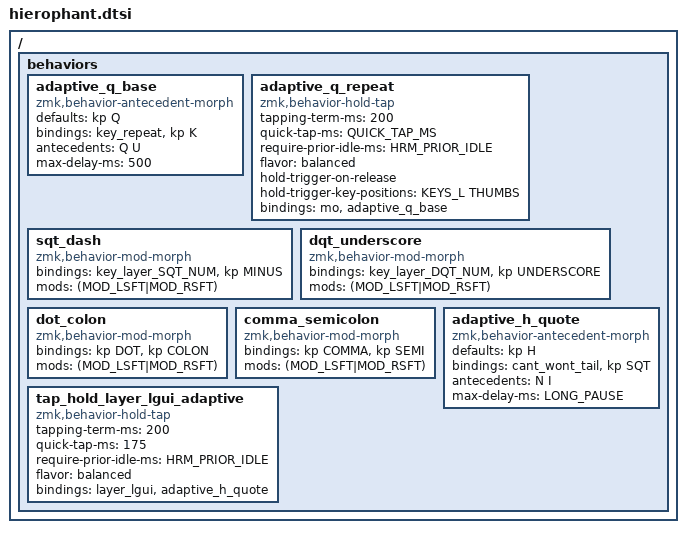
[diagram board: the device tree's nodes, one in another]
ZMK_SIMPLE_MACRO(cant_wont_tail, <&kp SQT>, <&kp T>)
ZMK_SIMPLE_MACRO(dot_slash, <&kp DOT>, <&kp FSLH>)
/ {
	
	/*

	won't, can't  (no NH in english)
	i'd, i'll, i've (no IH)
	they're (no YH)


	*/


	
	behaviors {

		// Q with U->K antecedent
		adaptive_q_base: adaptive_q_base {
			compatible = "zmk,behavior-antecedent-morph";
			#binding-cells = <0>;
			defaults = <&kp Q>;
			bindings = <&key_repeat>, <&kp K>;
			antecedents = <Q U>;
			max-delay-ms = <500>;
		};

		adaptive_q_repeat: adaptive_q_repeat {
			compatible = "zmk,behavior-hold-tap";
			#binding-cells = <2>;
			tapping-term-ms = <200>;
			quick-tap-ms = <QUICK_TAP_MS>;
			require-prior-idle-ms = <HRM_PRIOR_IDLE>;
			flavor = "balanced";
			hold-trigger-on-release;
			hold-trigger-key-positions = <KEYS_L THUMBS>;
			bindings = <&mo>, <&adaptive_q_base>;
		};


		// todo: use this to remake adaptive_q_repeat
		MAKE_ANTECEDENT_MORPH(adaptive_q_k, Q, K, U)

		MAKE_ADAPTIVE_REPEAT(adaptive_w_repeat, tlr, NUMPAD, W)

		MAKE_ADAPTIVE_REPEAT(adaptive_u_repeat, tll, SYMBOL, U)
		MAKE_ADAPTIVE_REPEAT(adaptive_d_repeat, tlr, SYMBOL, D)

		MAKE_ADAPTIVE_REPEAT(adaptive_z_repeat, tll_sticky, EXTRA, Z)
		MAKE_ADAPTIVE_REPEAT(adaptive_l_repeat, tlr_sticky, EXTRA, L)

		MAKE_ADAPTIVE_REPEAT(adaptive_f_repeat, tll_sticky, FN, F)
		MAKE_ADAPTIVE_REPEAT(adaptive_b_repeat, tlr_sticky, FN, B)
		
		MAKE_ADAPTIVE_REPEAT(adaptive_i_repeat, hml, LALT, I)
		MAKE_ADAPTIVE_REPEAT(adaptive_e_repeat, hml, LSHIFT, E)
		MAKE_ADAPTIVE_REPEAT(adaptive_a_repeat, hml, LCTRL, A)
		MAKE_ADAPTIVE_REPEAT(adaptive_p_repeat, tll, NUM, P)

		MAKE_ADAPTIVE_REPEAT(adaptive_g_repeat, tlr, NUM, G)
		MAKE_ADAPTIVE_REPEAT(adaptive_s_repeat, hmr, RCTRL, S)
		MAKE_ADAPTIVE_REPEAT(adaptive_t_repeat, hmr, RSHIFT, T)
		MAKE_ADAPTIVE_REPEAT(adaptive_r_repeat, hmr, RALT, R)

		sqt_dash: sqt_dash {
			compatible = "zmk,behavior-mod-morph";
			#binding-cells = <0>;
			bindings = <&key_layer_SQT_NUM>, <&kp MINUS>;
			mods = <(MOD_LSFT|MOD_RSFT)>;
		};

		dqt_underscore: dqt_underscore {
			compatible = "zmk,behavior-mod-morph";
			#binding-cells = <0>;
			bindings = <&key_layer_DQT_NUM>, <&kp UNDERSCORE>;
			mods = <(MOD_LSFT|MOD_RSFT)>;
		};

		dot_colon: dot_colon {
			compatible = "zmk,behavior-mod-morph";
			#binding-cells = <0>;
			bindings = <&kp DOT>, <&kp COLON>;
			mods = <(MOD_LSFT|MOD_RSFT)>;
		};

		/*
		 * Comma is just a comma. It used to emit ", " -- comma and a
		 * space in one tap -- which is right for prose and wrong
		 * everywhere else: every list in code, every CSV, every
		 * "a,b" argument had a space to take back out. The space now
		 * lives on the key next door, which only becomes a space when
		 * a comma has just been typed, so prose still costs two keys
		 * and nothing else pays for it.
		 */
		comma_semicolon: comma_semicolon {
			compatible = "zmk,behavior-mod-morph";
			#binding-cells = <0>;
			bindings = <&kp COMMA>, <&kp SEMI>;
			mods = <(MOD_LSFT|MOD_RSFT)>;
		};

		/*
		 * Y, but a space straight after a comma -- the same trick the
		 * symbol layer plays with ` becoming / after ~. Y sits next to
		 * the comma on the bottom row, and "y" never follows a comma
		 * in English without a space in between, so the letter loses
		 * nothing.
		 */
		MAKE_ANTECEDENT_MORPH(y_comma_space, Y, SPACE, COMMA)

		adaptive_h_quote: adaptive_h_quote {
			compatible = "zmk,behavior-antecedent-morph";
			#binding-cells = <0>;
			defaults = <&kp H>;
			// One binding per antecedent, in order: after N you are writing
			// can't or won't, after I you are writing I'd, I'll or I've and
			// want the apostrophe alone. Both are safe because neither NH
			// nor IH occurs in English.
			bindings = <&cant_wont_tail>, <&kp SQT>;
			antecedents = <N I>;
			max-delay-ms = <LONG_PAUSE>;
		};

		MAKE_ANTECEDENT_MORPH_ADV(adaptive_j_dot, &kp J, &dot_slash, DOT)

		tap_hold_layer_lgui_adaptive: tap_hold_layer_lgui_adaptive {
			compatible = "zmk,behavior-hold-tap";
			#binding-cells = <2>;
			tapping-term-ms = <200>;
			quick-tap-ms = <175>;
			require-prior-idle-ms = <HRM_PRIOR_IDLE>;
			flavor = "balanced";
			bindings = <&layer_lgui>, <&adaptive_h_quote>;
		};
	};
	
};


#define HIEROPHANT_LZ &trans &trans &trans &trans &trans &trans
#define HIEROPHANT_LT_IN &adaptive_f_repeat  &adaptive_z_repeat  &adaptive_u_repeat  &adaptive_q_repeat NUMPAD 0  &backspace_word_delete
#define HIEROPHANT_LT &kp TILDE  HIEROPHANT_LT_IN
#define HIEROPHANT_LM_IN &tap_hold_layer_lgui_adaptive LGUI_NAV_L 0  &adaptive_i_repeat  &adaptive_e_repeat  &adaptive_a_repeat  &adaptive_p_repeat
#define HIEROPHANT_LM &sqt_dash  HIEROPHANT_LM_IN
#define HIEROPHANT_LB_IN &comma_semicolon  &y_comma_space  &kp K  &kp O  &kp X
#define HIEROPHANT_LB &kp LCTRL  HIEROPHANT_LB_IN
#define HIEROPHANT_LH &sl_sym_or_numpad  &arcane_nav_l NAV 0  &lgui_space_tab
#define HIEROPHANT_LH_5 &trans &trans HIEROPHANT_LH

#define HIEROPHANT_RZ &trans &trans &trans &trans &trans &trans
#define HIEROPHANT_RT_IN &kp RETURN  &adaptive_w_repeat  &adaptive_d_repeat  &adaptive_l_repeat  &adaptive_b_repeat
#define HIEROPHANT_RT HIEROPHANT_RT_IN  &kp SEMI
#define HIEROPHANT_RM_IN &adaptive_g_repeat  &adaptive_s_repeat  &adaptive_t_repeat  &adaptive_r_repeat  &tap_hold_layer_rgui RGUI_NAV_R N
#define HIEROPHANT_RM HIEROPHANT_RM_IN  &dqt_underscore
#define HIEROPHANT_RB_IN &kp V  &kp C  &kp M  &adaptive_j_dot  &dot_colon
#define HIEROPHANT_RB HIEROPHANT_RB_IN  &kp FSLH
#define HIEROPHANT_RH &rgui_space_ret   &arcane_nav_r NAV 0  &sl_num_or_word
#define HIEROPHANT_RH_5 &trans &trans HIEROPHANT_RH
